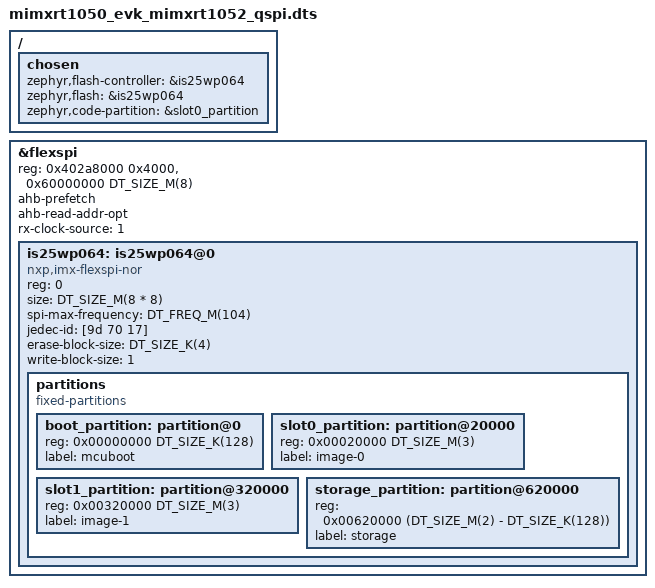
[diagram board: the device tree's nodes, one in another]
/*
 * Copyright (c) 2017, NXP
 *
 * SPDX-License-Identifier: Apache-2.0
 */

#include "mimxrt1050_evk.dtsi"

/ {
	chosen {
		zephyr,flash-controller = &is25wp064;
		zephyr,flash = &is25wp064;
		zephyr,code-partition = &slot0_partition;
	};
};

&flexspi {
	reg = <0x402a8000 0x4000>, <0x60000000 DT_SIZE_M(8)>;
	ahb-prefetch;
	ahb-read-addr-opt;
	rx-clock-source = <1>;
	status = "okay";

	is25wp064: is25wp064@0 {
		compatible = "nxp,imx-flexspi-nor";
		reg = <0>;
		size = <DT_SIZE_M(8 * 8)>;
		spi-max-frequency = <DT_FREQ_M(104)>;
		jedec-id = [9d 70 17];
		erase-block-size = <DT_SIZE_K(4)>;
		write-block-size = <1>;
		status = "okay";

		partitions {
			compatible = "fixed-partitions";
			#address-cells = <1>;
			#size-cells = <1>;

			/*
			 * Partition sizes must be aligned
			 * to the flash memory sector size of 4KB.
			 */
			boot_partition: partition@0 {
				reg = <0x00000000 DT_SIZE_K(128)>;
				label = "mcuboot";
			};

			slot0_partition: partition@20000 {
				reg = <0x00020000 DT_SIZE_M(3)>;
				label = "image-0";
			};

			slot1_partition: partition@320000 {
				reg = <0x00320000 DT_SIZE_M(3)>;
				label = "image-1";
			};

			storage_partition: partition@620000 {
				reg = <0x00620000 (DT_SIZE_M(2) - DT_SIZE_K(128))>;
				label = "storage";
			};
		};
	};
};
